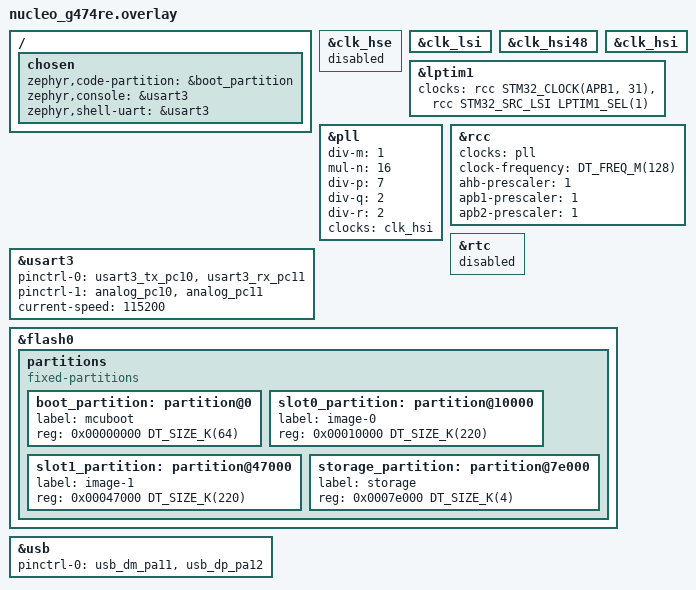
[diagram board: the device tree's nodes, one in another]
/ {
        chosen {
//                zephyr,shell-uart = &cdc_acm_uart0;
                zephyr,code-partition = &boot_partition;
                zephyr,console = &usart3;
                zephyr,shell-uart = &usart3;
        };
};

	&clk_hse {
		status = "disabled";
	};
	&clk_lsi {
		status = "okay";
	};

	&clk_hsi48 {
		status = "okay";
	};

	&clk_hsi {
		status = "okay";
	};

	stm32_lp_tick_source: &lptim1 {
		clocks = <&rcc STM32_CLOCK(APB1, 31)>,
			 <&rcc STM32_SRC_LSI LPTIM1_SEL(1)>;
		status = "okay";
	};

&pll {
	div-m = <1>;
	mul-n = <16>;
	div-p = <7>;
	div-q = <2>;
	div-r = <2>;
	clocks = <&clk_hsi>;
	status = "okay";
};

&rcc {
	clocks = <&pll>;
	clock-frequency = <DT_FREQ_M(128)>;
	ahb-prescaler = <1>;
	apb1-prescaler = <1>;
	apb2-prescaler = <1>;
};

&usart3 {
	pinctrl-0 = <&usart3_tx_pc10 &usart3_rx_pc11>;
	pinctrl-1 = <&analog_pc10 &analog_pc11>;
	pinctrl-names = "default", "sleep";
	current-speed = <115200>;
	status = "okay";
};

	&rtc {
		status = "disabled";
	};

/delete-node/ &slot0_partition;
/delete-node/ &slot1_partition;
/delete-node/ &boot_partition;
/delete-node/ &storage_partition;

&flash0 {
	partitions {
		compatible = "fixed-partitions";
		#address-cells = <1>;
		#size-cells = <1>;

		boot_partition: partition@0 {
			label = "mcuboot";
			reg = <0x00000000 DT_SIZE_K(64)>;
		};

		slot0_partition: partition@10000 {
			label = "image-0";
			reg = <0x00010000 DT_SIZE_K(220)>;
		};

		slot1_partition: partition@47000 {
			label = "image-1";
			reg = <0x00047000 DT_SIZE_K(220)>;
		};

		/* Set 4Kb of storage at the end of the 512Kb of flash */
		storage_partition: partition@7e000 {
			label = "storage";
			reg = <0x0007e000 DT_SIZE_K(4)>;
		};
	};
};


zephyr_udc0: &usb {
	pinctrl-0 = <&usb_dm_pa11 &usb_dp_pa12>;
	pinctrl-names = "default";
	status = "okay";
};
